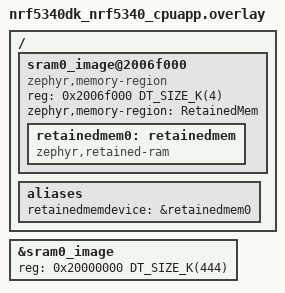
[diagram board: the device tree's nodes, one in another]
/ {
	sram0_image@2006f000 {
		compatible = "zephyr,memory-region", "mmio-sram";
		reg = <0x2006f000 DT_SIZE_K(4)>;
		zephyr,memory-region = "RetainedMem";
		status = "okay";

		retainedmem0: retainedmem {
			compatible = "zephyr,retained-ram";
			status = "okay";
		};
	};

	aliases {
		retainedmemdevice = &retainedmem0;
	};
};

&sram0_image {
	/* Shrink SRAM size to avoid overlap with retained memory region */
	reg = <0x20000000 DT_SIZE_K(444)>;
};
